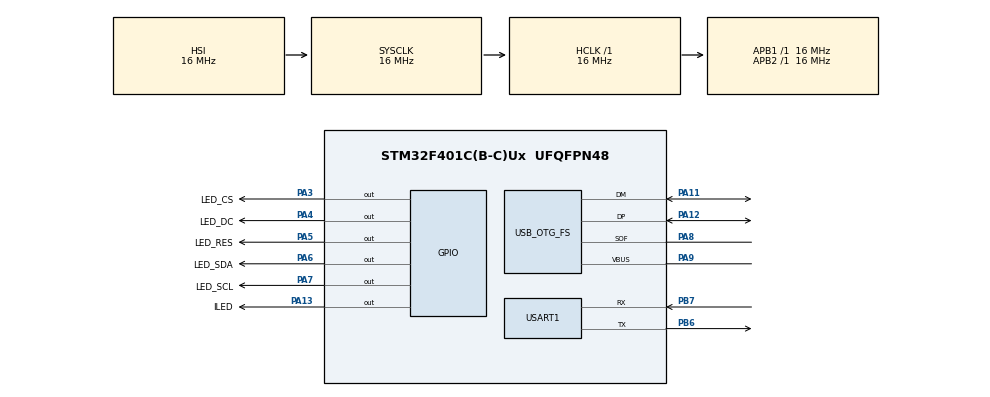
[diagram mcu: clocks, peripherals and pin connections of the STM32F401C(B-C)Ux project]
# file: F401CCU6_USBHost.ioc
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Mcu.Family=STM32F4
Mcu.Name=STM32F401C(B-C)Ux
Mcu.Package=UFQFPN48
NVIC.OTG_FS_IRQn=true\:0\:0\:false\:false\:true\:false\:true\:true
NVIC.PriorityGroup=NVIC_PRIORITYGROUP_4
PA11.Mode=Host_Only
PA11.Signal=USB_OTG_FS_DM
PA12.Mode=Host_Only
PA12.Signal=USB_OTG_FS_DP
PA13.GPIO_Label=ILED
PA13.GPIO_PuPd=GPIO_NOPULL
PA13.PinState=GPIO_PIN_RESET
PA13.Signal=GPIO_Output
PA3.GPIO_Label=LED_CS
PA3.GPIO_Speed=GPIO_SPEED_FREQ_VERY_HIGH
PA3.Signal=GPIO_Output
PA4.GPIO_Label=LED_DC
PA4.GPIO_Speed=GPIO_SPEED_FREQ_VERY_HIGH
PA4.Signal=GPIO_Output
PA5.GPIO_Label=LED_RES
PA5.GPIO_Speed=GPIO_SPEED_FREQ_VERY_HIGH
PA5.Signal=GPIO_Output
PA6.GPIO_Label=LED_SDA
PA6.GPIO_Speed=GPIO_SPEED_FREQ_VERY_HIGH
PA6.Signal=GPIO_Output
PA7.GPIO_Label=LED_SCL
PA7.GPIO_Speed=GPIO_SPEED_FREQ_VERY_HIGH
PA7.Signal=GPIO_Output
PA8.Mode=Activate_SOF_FS
PA8.Signal=USB_OTG_FS_SOF
PA9.Mode=Activate_VBUS
PA9.Signal=USB_OTG_FS_VBUS
PB6.Mode=Multiprocessor_communication
PB6.Signal=USART1_TX
PB7.Mode=Multiprocessor_communication
PB7.Signal=USART1_RX
PC14-OSC32_IN.Mode=LSE-External-Oscillator
PC14-OSC32_IN.Signal=RCC_OSC32_IN
PC15-OSC32_OUT.Mode=LSE-External-Oscillator
PC15-OSC32_OUT.Signal=RCC_OSC32_OUT
PH0\ -\ OSC_IN.Mode=HSE-External-Oscillator
PH0\ -\ OSC_IN.Signal=RCC_OSC_IN
PH1\ -\ OSC_OUT.Mode=HSE-External-Oscillator
PH1\ -\ OSC_OUT.Signal=RCC_OSC_OUT
ProjectManager.HeapSize=0x200
ProjectManager.StackSize=0x400
ProjectManager.TargetToolchain=STM32CubeIDE
RCC.48MHZClocksFreq_Value=48000000
RCC.AHBFreq_Value=16000000
RCC.APB1Freq_Value=16000000
RCC.APB2Freq_Value=16000000
RCC.CortexFreq_Value=16000000
RCC.HSE_VALUE=25000000
RCC.HSI_VALUE=16000000
RCC.PLLM=15
RCC.PLLN=144
RCC.PLLQ=5
RCC.SYSCLKFreq_VALUE=16000000
RCC.VCOOutputFreq_Value=240000000
USART1.VirtualMode=VM_ASYNC
USB_HOST.USBH_HandleTypeDef=hUsbHostFS
USB_HOST.VirtualModeFS=Hid
USB_OTG_FS.VirtualMode=Host_Only
USB_OTG_FS.phy_itface=HCD_PHY_EMBEDDED
VP_CRC_VS_CRC.Mode=CRC_Activate
VP_USB_HOST_VS_USB_HOST_HID_FS.Mode=HID_FS
board=custom

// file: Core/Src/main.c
/* USER CODE BEGIN Header */
/**
  ******************************************************************************
  * @file           : main.c
  * @brief          : Main program body
  ******************************************************************************
  * @attention
  *
  * Copyright (c) 2023 STMicroelectronics.
  * All rights reserved.
  *
  * This software is licensed under terms that can be found in the LICENSE file
  * in the root directory of this software component.
  * If no LICENSE file comes with this software, it is provided AS-IS.
  *
  ******************************************************************************
  */
/* USER CODE END Header */
#include "main.h"
#include "usb_host.h"

/* USER CODE BEGIN Includes */
#include "OLED.h"
/* USER CODE END Includes */

/* USER CODE BEGIN PD */
#define LED_On()		HAL_GPIO_WritePin(ILED_GPIO_Port, ILED_Pin, GPIO_PIN_SET);
#define LED_Off()		HAL_GPIO_WritePin(ILED_GPIO_Port, ILED_Pin, GPIO_PIN_RESET);
/* USER CODE END PD */

CRC_HandleTypeDef hcrc;

UART_HandleTypeDef huart1;

void SystemClock_Config(void);
static void MX_GPIO_Init(void);
static void MX_CRC_Init(void);
static void MX_USART1_UART_Init(void);
void MX_USB_HOST_Process(void);

int main(void)
{

  /* MCU Configuration--------------------------------------------------------*/

  /* Reset of all peripherals, Initializes the Flash interface and the Systick. */
  HAL_Init();

  /* Configure the system clock */
  SystemClock_Config();

  /* Initialize all configured peripherals */
  MX_GPIO_Init();
  MX_CRC_Init();
  MX_USART1_UART_Init();
  MX_USB_HOST_Init();
  /* USER CODE BEGIN 2 */
  OLED_Init();
  LED_Off();
  /* USER CODE END 2 */

  /* Infinite loop */
  /* USER CODE BEGIN WHILE */
  while (1)
  {
	  LED_On();
	  OLED_ShowString(1,1,"InitComp");
    /* USER CODE END WHILE */
    MX_USB_HOST_Process();

  }
}

void SystemClock_Config(void)
{
  RCC_OscInitTypeDef RCC_OscInitStruct = {0};
  RCC_ClkInitTypeDef RCC_ClkInitStruct = {0};

  /** Configure the main internal regulator output voltage
  */
  __HAL_RCC_PWR_CLK_ENABLE();
  __HAL_PWR_VOLTAGESCALING_CONFIG(PWR_REGULATOR_VOLTAGE_SCALE2);

  /** Initializes the RCC Oscillators according to the specified parameters
  * in the RCC_OscInitTypeDef structure.
  */
  RCC_OscInitStruct.OscillatorType = RCC_OSCILLATORTYPE_HSI|RCC_OSCILLATORTYPE_HSE;
  RCC_OscInitStruct.HSEState = RCC_HSE_ON;
  RCC_OscInitStruct.HSIState = RCC_HSI_ON;
  RCC_OscInitStruct.HSICalibrationValue = RCC_HSICALIBRATION_DEFAULT;
  RCC_OscInitStruct.PLL.PLLState = RCC_PLL_ON;
  RCC_OscInitStruct.PLL.PLLSource = RCC_PLLSOURCE_HSE;
  RCC_OscInitStruct.PLL.PLLM = 15;
  RCC_OscInitStruct.PLL.PLLN = 144;
  RCC_OscInitStruct.PLL.PLLP = RCC_PLLP_DIV2;
  RCC_OscInitStruct.PLL.PLLQ = 5;
  if (HAL_RCC_OscConfig(&RCC_OscInitStruct) != HAL_OK)
  {
    Error_Handler();
  }

  /** Initializes the CPU, AHB and APB buses clocks
  */
  RCC_ClkInitStruct.ClockType = RCC_CLOCKTYPE_HCLK|RCC_CLOCKTYPE_SYSCLK
                              |RCC_CLOCKTYPE_PCLK1|RCC_CLOCKTYPE_PCLK2;
  RCC_ClkInitStruct.SYSCLKSource = RCC_SYSCLKSOURCE_HSI;
  RCC_ClkInitStruct.AHBCLKDivider = RCC_SYSCLK_DIV1;
  RCC_ClkInitStruct.APB1CLKDivider = RCC_HCLK_DIV1;
  RCC_ClkInitStruct.APB2CLKDivider = RCC_HCLK_DIV1;

  if (HAL_RCC_ClockConfig(&RCC_ClkInitStruct, FLASH_LATENCY_0) != HAL_OK)
  {
    Error_Handler();
  }
}

static void MX_CRC_Init(void)
{

  hcrc.Instance = CRC;
  if (HAL_CRC_Init(&hcrc) != HAL_OK)
  {
    Error_Handler();
  }

}

static void MX_USART1_UART_Init(void)
{

  huart1.Instance = USART1;
  huart1.Init.BaudRate = 115200;
  huart1.Init.WordLength = UART_WORDLENGTH_8B;
  huart1.Init.StopBits = UART_STOPBITS_1;
  huart1.Init.Parity = UART_PARITY_NONE;
  huart1.Init.Mode = UART_MODE_TX_RX;
  huart1.Init.HwFlowCtl = UART_HWCONTROL_NONE;
  huart1.Init.OverSampling = UART_OVERSAMPLING_16;
  if (HAL_MultiProcessor_Init(&huart1, 0, UART_WAKEUPMETHOD_IDLELINE) != HAL_OK)
  {
    Error_Handler();
  }

}

static void MX_GPIO_Init(void)
{
  GPIO_InitTypeDef GPIO_InitStruct = {0};

  /* GPIO Ports Clock Enable */
  __HAL_RCC_GPIOC_CLK_ENABLE();
  __HAL_RCC_GPIOH_CLK_ENABLE();
  __HAL_RCC_GPIOA_CLK_ENABLE();
  __HAL_RCC_GPIOB_CLK_ENABLE();

  /*Configure GPIO pin Output Level */
  HAL_GPIO_WritePin(GPIOA, LED_CS_Pin|LED_DC_Pin|LED_RES_Pin|LED_SDA_Pin
                          |LED_SCL_Pin|ILED_Pin, GPIO_PIN_RESET);

  /*Configure GPIO pins : LED_CS_Pin LED_DC_Pin LED_RES_Pin LED_SDA_Pin
                           LED_SCL_Pin */
  GPIO_InitStruct.Pin = LED_CS_Pin|LED_DC_Pin|LED_RES_Pin|LED_SDA_Pin
                          |LED_SCL_Pin;
  GPIO_InitStruct.Mode = GPIO_MODE_OUTPUT_PP;
  GPIO_InitStruct.Pull = GPIO_NOPULL;
  GPIO_InitStruct.Speed = GPIO_SPEED_FREQ_VERY_HIGH;
  HAL_GPIO_Init(GPIOA, &GPIO_InitStruct);

  /*Configure GPIO pin : ILED_Pin */
  GPIO_InitStruct.Pin = ILED_Pin;
  GPIO_InitStruct.Mode = GPIO_MODE_OUTPUT_PP;
  GPIO_InitStruct.Pull = GPIO_NOPULL;
  GPIO_InitStruct.Speed = GPIO_SPEED_FREQ_LOW;
  HAL_GPIO_Init(ILED_GPIO_Port, &GPIO_InitStruct);

}

void Error_Handler(void)
{
  __disable_irq();
  while (1)
  {
  }
}
